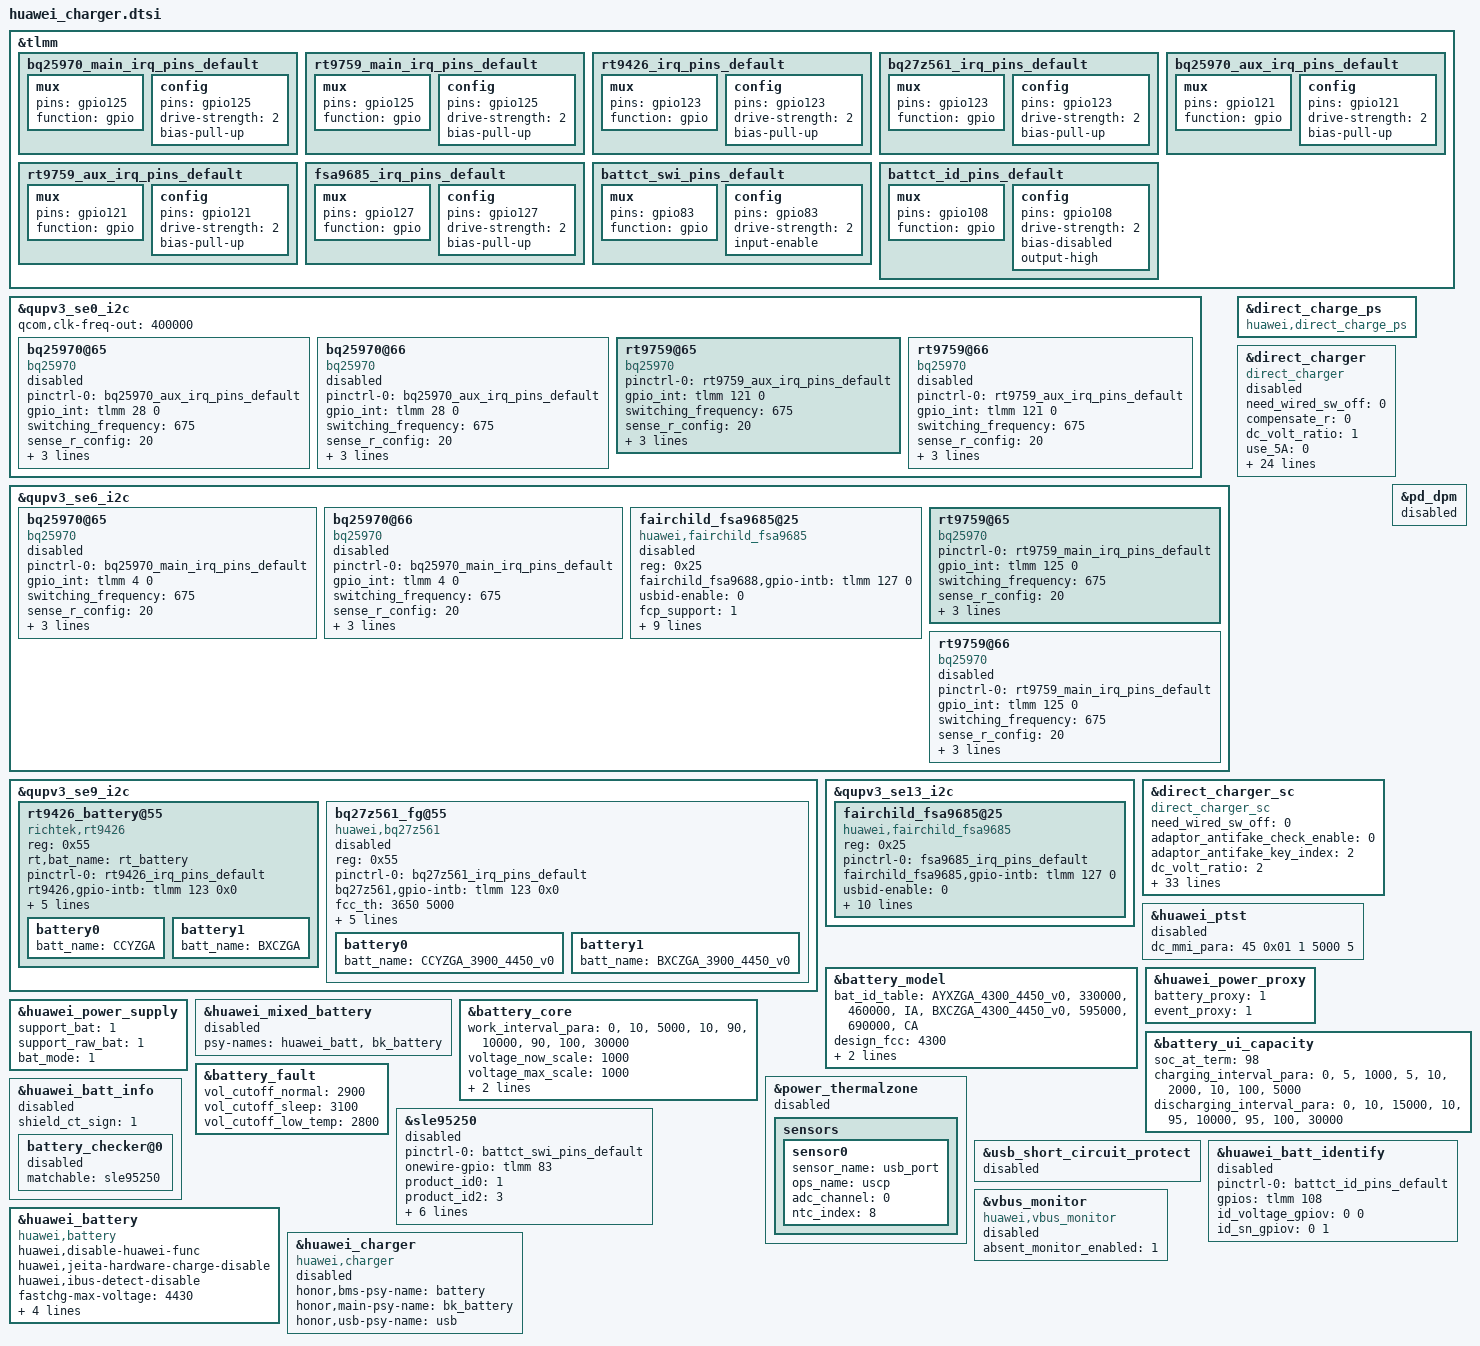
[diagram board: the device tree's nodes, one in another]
&tlmm {
	bq25970_main_irq_pins_default: bq25970_main_irq_pins_default {
		mux {
			pins = "gpio125";
			function = "gpio";
		};
		config {
			pins = "gpio125";
			drive-strength = <2>;
			bias-pull-up;
		};
	};
	
	rt9759_main_irq_pins_default: rt9759_main_irq_pins_default {
		mux {
			pins = "gpio125";
			function = "gpio";
		};
		config {
			pins = "gpio125";
			drive-strength = <2>;
			bias-pull-up;
		};
	};

	rt9426_irq_pins_default: rt9426_irq_pins_default {
		mux {
			pins = "gpio123";
			function = "gpio";
		};
		config {
			pins = "gpio123";
			drive-strength = <2>;
			bias-pull-up;
		};
	};

	bq27z561_irq_pins_default: bq27z561_irq_pins_default {
		mux {
			pins = "gpio123";
			function = "gpio";
		};
		config {
			pins = "gpio123";
			drive-strength = <2>;
			bias-pull-up;
		};
	};

	bq25970_aux_irq_pins_default: bq25970_aux_irq_pins_default {
		mux {
			pins = "gpio121";
			function = "gpio";
		};
		config {
			pins = "gpio121";
			drive-strength = <2>;
			bias-pull-up;
		};
	};

	rt9759_aux_irq_pins_default: rt9759_aux_irq_pins_default {
		mux {
			pins = "gpio121";
			function = "gpio";
		};
		config {
			pins = "gpio121";
			drive-strength = <2>;
			bias-pull-up;
		};
	};

	fsa9685_irq_pins_default: fsa9685_irq_pins_default {                              //no find, 9685->9688
		mux {
			pins = "gpio127";
			function = "gpio";
		};
		config {
			pins = "gpio127";
			drive-strength = <2>;
			bias-pull-up;
		};
	};
	battct_swi_pins_default: battct_swi_pins_default {
		mux {
			pins = "gpio83";
			function = "gpio";
		};
		config {
			pins = "gpio83";
			drive-strength = <2>;
			input-enable;
		};
	};
	battct_id_pins_default: battct_id_pins_default {
		mux {
			pins = "gpio108";
			function = "gpio";
		};
		config {
			pins = "gpio108";
			drive-strength = <2>;
			bias-disabled;
			output-high;
		};
	};
};

&qupv3_se0_i2c {
	qcom,clk-freq-out = <400000>; /* if bq27z561_fg is used, i2c clock must be 100k(100000) */
	status = "ok";
	bq25970@65 {
		compatible = "bq25970"; /* BQ25970YFFR SC */
		pinctrl-names = "default";
		pinctrl-0 = <&bq25970_aux_irq_pins_default>;
		gpio_int = <&tlmm 28 0>;
		switching_frequency = <675>;
		sense_r_config = <20>;
		sense_r_actual = <10>;
		reg = <0x65>;
		ic_role = <0>;
		status = "disabled";
	};

	bq25970@66 {
		compatible = "bq25970"; /* VerB:RT9759WSC VerA:SC8551*/
		pinctrl-names = "default";
		pinctrl-0 = <&bq25970_aux_irq_pins_default>;
		gpio_int = <&tlmm 28 0>;
		switching_frequency = <675>;
		sense_r_config = <20>;
		sense_r_actual = <10>;
		reg = <0x66>;
		ic_role = <0>;
		status = "disabled";
	};
	rt9759@65 {
		compatible = "bq25970"; /* BQ25970YFFR SC */
		pinctrl-names = "default";
		pinctrl-0 = <&rt9759_aux_irq_pins_default>;
		gpio_int = <&tlmm 121 0>;
		switching_frequency = <675>;
		sense_r_config = <20>;
		sense_r_actual = <10>;
		reg = <0x65>;
		ic_role = <0>;
		status = "ok";
	};
	rt9759@66 {
		compatible = "bq25970"; /* VerB:RT9759WSC VerA:SC8551*/
		pinctrl-names = "default";
		pinctrl-0 = <&rt9759_aux_irq_pins_default>;
		gpio_int = <&tlmm 121 0>;
		switching_frequency = <675>;
		sense_r_config = <20>;
		sense_r_actual = <10>;
		reg = <0x66>;
		ic_role = <0>;
		status = "disabled";
	};
};

&qupv3_se6_i2c {
	status = "ok";
	bq25970@65 {
		compatible = "bq25970";
		pinctrl-names = "default";
		pinctrl-0 = <&bq25970_main_irq_pins_default>;
		gpio_int = <&tlmm 4 0>;
		switching_frequency = <675>;
		sense_r_config = <20>;
		sense_r_actual = <10>;
		reg = <0x65>;
		ic_role = <1>;
		status = "disabled";
	};
	bq25970@66 {
		compatible = "bq25970"; /* VerB:RT9759WSC VerA:SC8551 */
		pinctrl-names = "default";
		pinctrl-0 = <&bq25970_main_irq_pins_default>;
		gpio_int = <&tlmm 4 0>;
		switching_frequency = <675>;
		sense_r_config = <20>;
		sense_r_actual = <10>;
		reg = <0x66>;
		ic_role = <1>;
		status = "disabled";
	};
	fairchild_fsa9685@25 {
		compatible = "huawei,fairchild_fsa9685";
		reg = <0x25>;
		pinctrl-names = "default";
		fairchild_fsa9688,gpio-intb = <&tlmm 127 0>;
		usbid-enable = <0>;
		fcp_support = <1>;
		scp_support = <1>;
		mhl_detect_disable = <1>;
		need_other_bc12 = <0>;
		ignore_force_ac = <1>;
		/* for rt8979 */
		interrupt-names = "vbus_change", "device_change", "detach",
		              "attach";
		/* auto_switch; */
		scp;
		dcd;
		dcd_timeout = <600>;  /* ms */
		intb_watchdog = <1000>;  /* ms */
		ovp_sel = <14500000>;  /* uV */
		status = "disabled";
	};
	rt9759@65 {
		compatible = "bq25970"; /* BQ25970YFFR SC */
		pinctrl-names = "default";
		pinctrl-0 = <&rt9759_main_irq_pins_default>;
		gpio_int = <&tlmm 125 0>;
		switching_frequency = <675>;
		sense_r_config = <20>;
		sense_r_actual = <10>;
		reg = <0x65>;
		ic_role = <1>;
		status = "ok";
	};
	rt9759@66 {
		compatible = "bq25970"; /* VerB:RT9759WSC VerA:SC8551*/
		pinctrl-names = "default";
		pinctrl-0 = <&rt9759_main_irq_pins_default>;
		gpio_int = <&tlmm 125 0>;
		switching_frequency = <675>;
		sense_r_config = <20>;
		sense_r_actual = <10>;
		reg = <0x66>;
		ic_role = <1>;
		status = "disabled";
	};
};

&qupv3_se9_i2c {
	status = "ok";
	rt9426_battery@55{
		reg = <0x55>;
		rt,bat_name = "rt_battery";
		compatible = "richtek,rt9426";
		pinctrl-names = "default";
		pinctrl-0 = <&rt9426_irq_pins_default>;
		rt9426,gpio-intb = <&tlmm 123 0x0>;
		ntc_compensation_is = <1>;
		ntc_temp_compensation_para =
			"11000", "140",
			"10000", "120",
			"9000", "100",
			"8000", "80",
			"7000", "60",
			"6000", "50",
			"5000", "40",
			"3000", "20",
			"2000", "10";
		rt9426_config_ver = <1>;
		status = "ok";
		battery0{
			batt_name = "CCYZGA";
			#include "../../../huawei_charger/rt9426_CCYZGA_4V45_3900mah_BT216.dtsi"
		};
		battery1{
			batt_name = "BXCZGA";
			#include "../../../huawei_charger/rt9426_BXCZGA_4V45_3900mah_BT216.dtsi"
		};
	};

	bq27z561_fg@55 {
		reg = <0x55>;
		compatible = "huawei,bq27z561";
		status = "disabled";
		pinctrl-names = "default";
		pinctrl-0 = <&bq27z561_irq_pins_default>;
		bq27z561,gpio-intb = <&tlmm 123 0x0>;
		fcc_th = <3650 5000>;
		qmax_th = <3850 5000>;
		ntc_compensation_is = <1>;
		ntc_temp_compensation_para =
			"11000", "140",
			"10000", "120",
			"9000", "100",
			"8000", "80",
			"7000", "60",
			"6000", "50",
			"5000", "40",
			"3000", "20",
			"2000", "10";
		battery0{
			batt_name = "CCYZGA_3900_4450_v0";
			#include "../../../huawei_charger/ti_CCYZGA_4440_3900mah_BT216.dtsi"
		};
		battery1{
			batt_name = "BXCZGA_3900_4450_v0";
			#include "../../../huawei_charger/ti_BXCZGA_4440_3900mah_BT216.dtsi"
		};
	};
};
&qupv3_se13_i2c {
	status = "ok";
	fairchild_fsa9685@25 {
		compatible = "huawei,fairchild_fsa9685";
		reg = <0x25>;
		pinctrl-names = "default";
		pinctrl-0 = <&fsa9685_irq_pins_default>;
		fairchild_fsa9685,gpio-intb = <&tlmm 127 0>;
		usbid-enable = <0>;
		fcp_support = <1>;
		scp_support = <1>;
		mhl_detect_disable = <1>;
		need_other_bc12 = <0>;
		ignore_force_ac = <1>;
		/* for rt8979 */
		interrupt-names = "vbus_change", "device_change", "detach",
		              "attach";
		/* auto_switch; */
		scp;
		dcd;
		dcd_timeout = <600>;  /* ms */
		intb_watchdog = <1000>;  /* ms */
		ovp_sel = <14500000>;  /* uV */
		status = "ok";
	};
};

&direct_charge_ps {
	compatible = "huawei,direct_charge_ps";
	status = "ok";
};

&direct_charger{
	need_wired_sw_off = <0>;
	compensate_r = <0>;
	dc_volt_ratio = <1>;
	use_5A = <0>;
	scp_cable_detect_enable = <0>;
	max_adaptor_vset = <5500>;
	max_tadapt = <115>;
	max_tls = <115>;
	ibat_abnormal_th = <200>;
	first_cc_stage_timer_in_min = <0>;
	max_dc_bat_vol = <4350>;
	min_dc_bat_vol = <3550>;
	charge_control_interval = <5>;
	threshold_caculation_interval = <5>;
	safety_monitor_interval = <5>;
	scp_work_on_charger = <0>;
	init_adapter_vset = <4400>;
	init_delt_vset = <300>;
	vstep = <10>;
	delta_err = <200>;
	vol_err_th = <150>;
	full_path_res_max = <120>;
	standard_cable_full_path_res_max = <160>;
	max_current_for_none_standard_cable = <3000>;
	adaptor_leakage_current_th = <300>;
	stage_need_to_jump = "-1";
	temp_para =
		"-32767", "10", "0",
		"10", "45", "4750",
		"45", "32767", "0";
	compatible = "direct_charger";
	status = "disabled";
};

&direct_charger_sc{
	compatible = "direct_charger_sc";
	need_wired_sw_off = <0>;
	adaptor_antifake_check_enable = <0>;
	adaptor_antifake_key_index = <2>;
	dc_volt_ratio = <2>;
	max_adaptor_vset = <11000>;
	max_tadapt = <115>;
	max_tls = <115>;
	ibat_abnormal_th = <200>;
	first_cc_stage_timer_in_min = <10>;
	max_dc_bat_vol = <4380>;
	min_dc_bat_vol = <3550>;
	charge_control_interval = <5>;
	threshold_caculation_interval = <5>;
	safety_monitor_interval = <5>;
	scp_work_on_charger = <1>;
	init_adapter_vset = <8800>;
	init_delt_vset = <600>;
	vstep = <20>;
	delta_err = <300>;
	vol_err_th = <150>;
	full_path_res_max = <500>;
	standard_cable_full_path_res_max = <500>;
	max_current_for_none_standard_cable = <8000>;
	adaptor_leakage_current_th = <300>;
	stage_need_to_jump = "-1";
	compensate_r = <0>;
	cc_cable_detect_enable = <1>;
	cc_unsafe_sc_enable = <1>;
	is_show_ico_first = <1>;
	support_multi_ic = <1>;
	ui_max_pwr = <40000>;
	volt_para =
		"4250", "8000", "6000",
		"4350", "6000", "5200",
		"4380", "5200", "4000",
		"4430", "4000", "1200";
	temp_para =
		"-32767", "10", "0",
		"10", "45", "8000",
		"45", "32767", "0";
	resist_para =
		"0", "300", "8000",
		"300", "500", "4000";
	std_resist_para =
		"0", "300", "8000",
		"300", "500", "4000";
	status = "ok";
};

&pd_dpm {
	status = "disabled";
};
&huawei_ptst {
	dc_mmi_para = <45 0x01 1 5000 5>;
	status = "disabled";
};
&battery_model {
	bat_id_table =
		"AYXZGA_4300_4450_v0", "330000", "460000", "IA",
		"BXCZGA_4300_4450_v0","595000","690000","CA";
	design_fcc = <4300>;
	//io-channels = <&pmi632_vadc ADC_BAT_ID_PU2>;
	//io-channel-names = "batt-id";
	support_iio = <1>;
	id_adc_channel = <0>; /* useless but necessary for Qcom, set 0 as default */
	status = "ok";
};
&huawei_power_proxy {
	battery_proxy = <1>;
	event_proxy = <1>;
	status = "ok";
};

&huawei_power_supply {
	support_bat = <1>;
	support_raw_bat = <1>;
	bat_mode = <1>;
	status = "ok";
};

&huawei_mixed_battery {
	psy-names = "huawei_batt", "bk_battery";
	status = "disabled";
};
&battery_core {
	work_interval_para =
          "0","10","5000",
          "10","90","10000",
          "90","100","30000";
	voltage_now_scale = <1000>;
	voltage_max_scale = <1000>;
	charge_fcc_scale = <1000>;
	charge_rm_scale = <1000>;
	status = "ok";
};

&battery_ui_capacity {
	soc_at_term	= <98>;
	charging_interval_para =
            "0", "5", "1000",
            "5", "10", "2000",
            "10", "100", "5000";
	discharging_interval_para =
                        "0", "10", "15000",
                      "10", "95", "10000",
                     "95", "100", "30000";
	status = "ok";
};

&battery_fault {
	vol_cutoff_normal = <2900>;
	vol_cutoff_sleep = <3100>;
	vol_cutoff_low_temp = <2800>;
	status = "ok";
};

&power_thermalzone {
	status = "disabled";
	sensors{
		sensor0 {
			sensor_name = "usb_port";
			ops_name = "uscp";
			adc_channel = <0>;
			ntc_index = <8>;
		};
	};
};

&sle95250 {
	pinctrl-names = "default";
	pinctrl-0 = <&battct_swi_pins_default>;
	onewire-gpio = <&tlmm 83 0>;
	product_id0 = <1>;
	product_id2 = <3>;
	gpio_sn_mode_val = <1>;
	dip_check = <0>;
	gpio_swi = <83>;
	gpio_id_mode = <108>;
	gpio_swi_drv = <3>;
	tau = /bits/ 8 <10>;
	status = "disabled";
};

&usb_short_circuit_protect {
	pinctrl-names = "default";
	//pinctrl-0 = <&mos_en_default>;
	//gpio_usb_short_circuit_protect = <&pmi632_gpios 2 0>;
	status = "disabled";
};

&huawei_batt_identify {
	pinctrl-names = "default";
	pinctrl-0 = <&battct_id_pins_default>;
	gpios = <&tlmm 108 0>;
	id_voltage_gpiov = <0 0>;
	id_sn_gpiov = <0 1>;
	status = "disabled";
};

&huawei_batt_info {
	status = "disabled";
	shield_ct_sign = <1>;
	battery_checker@0 {
		matchable = <&sle95250>;
		status = "disabled";
	};
};

&huawei_battery {
	compatible = "huawei,battery";
	status = "ok";
	huawei,disable-huawei-func;
	huawei,jeita-hardware-charge-disable;
	huawei,ibus-detect-disable;
	fastchg-max-voltage = <4430>;
	huawei,bms-psy-name = "bk_battery";
	huawei,bk_battery-psy-name = "bk_battery";
	huawei,usb-psy-name = "usb";
	use_third_coul = <1>;
};

&huawei_charger {
	compatible = "huawei,charger";
	honor,bms-psy-name = "battery";
	honor,main-psy-name = "bk_battery";
	honor,usb-psy-name = "usb";
	status = "disabled";
};

&vbus_monitor {
	compatible = "huawei,vbus_monitor";
	absent_monitor_enabled = <1>;
	status = "disabled";
};
